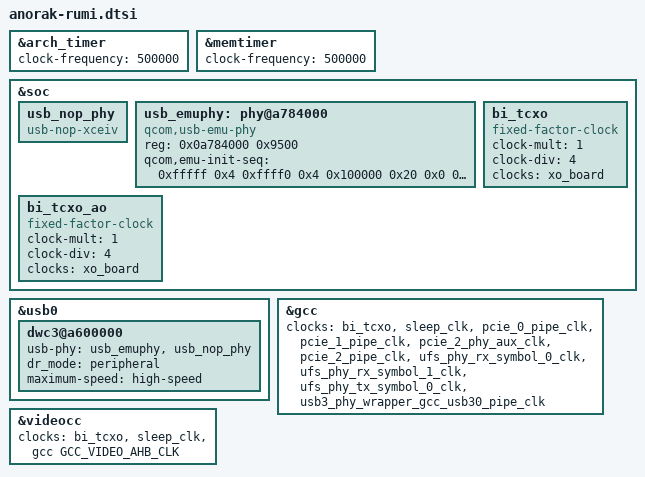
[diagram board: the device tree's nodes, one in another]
#include <dt-bindings/clock/qcom,gcc-anorak.h>

&arch_timer {
	clock-frequency = <500000>;
};

&memtimer {
	clock-frequency = <500000>;
};

&soc {
	usb_nop_phy: usb_nop_phy {
		compatible = "usb-nop-xceiv";
	};

	usb_emuphy: phy@a784000 {
		compatible = "qcom,usb-emu-phy";
		reg = <0x0a784000 0x9500>;

		qcom,emu-init-seq = <0xfffff 0x4
			0xffff0 0x4
			0x100000 0x20
			0x0 0x20
			0x000101F0 0x20
			0x00100000 0x3c
			0x0 0x3c
			0x0 0x4>;
	};

	bi_tcxo: bi_tcxo {
		compatible = "fixed-factor-clock";
		clock-mult = <1>;
		clock-div = <4>;
		clocks = <&xo_board>;
		#clock-cells = <0>;
	};

	bi_tcxo_ao: bi_tcxo_ao {
		compatible = "fixed-factor-clock";
		clock-mult = <1>;
		clock-div = <4>;
		clocks = <&xo_board>;
		#clock-cells = <0>;
	};
};

&usb0 {
	dwc3@a600000 {
		usb-phy = <&usb_emuphy>, <&usb_nop_phy>;
		dr_mode = "peripheral";
		maximum-speed = "high-speed";
	};

};

&gcc {
	clocks = <&bi_tcxo>, <&sleep_clk>,
		<&pcie_0_pipe_clk>, <&pcie_1_pipe_clk>,
		<&pcie_2_phy_aux_clk>, <&pcie_2_pipe_clk>,
		<&ufs_phy_rx_symbol_0_clk>, <&ufs_phy_rx_symbol_1_clk>,
		<&ufs_phy_tx_symbol_0_clk>, <&usb3_phy_wrapper_gcc_usb30_pipe_clk>;
};

&videocc {
	clocks = <&bi_tcxo>, <&sleep_clk>,
		<&gcc GCC_VIDEO_AHB_CLK>;
};
